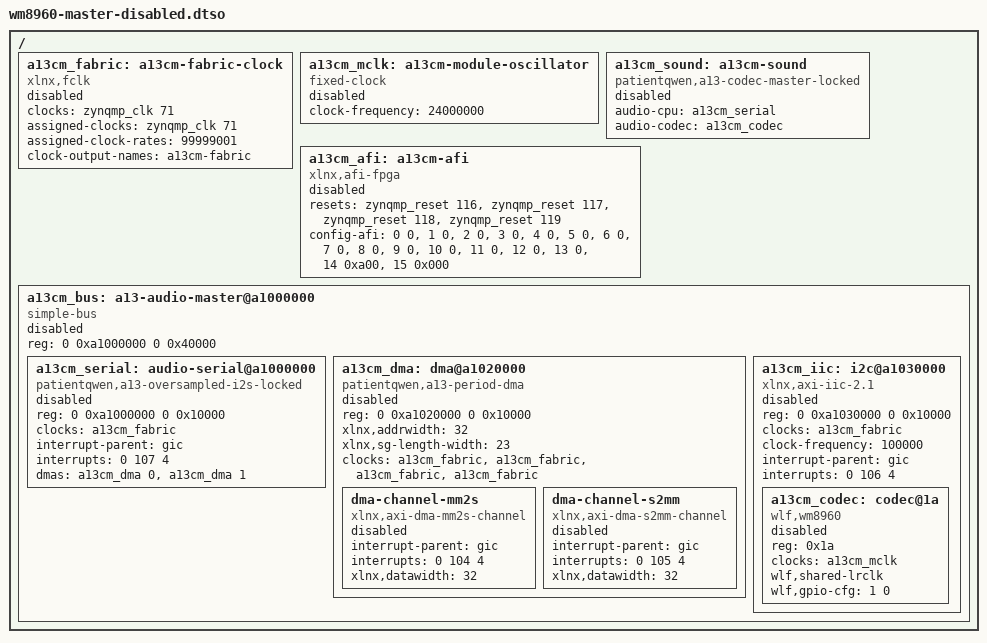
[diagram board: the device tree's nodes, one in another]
/dts-v1/;
/plugin/;

/* Offline candidate only: every new node remains disabled. No fpga-region. */
/ {
    fragment@0 {
        target-path = "/";
        __overlay__ {
            a13cm_fabric: a13cm-fabric-clock {
                compatible = "xlnx,fclk";
                #clock-cells = <0>;
                clocks = <&zynqmp_clk 71>;
                assigned-clocks = <&zynqmp_clk 71>;
                assigned-clock-rates = <99999001>;
                clock-output-names = "a13cm-fabric";
                status = "disabled";
            };
            a13cm_mclk: a13cm-module-oscillator {
                compatible = "fixed-clock";
                #clock-cells = <0>;
                clock-frequency = <24000000>;
                status = "disabled";
            };
            a13cm_sound: a13cm-sound {
                compatible = "patientqwen,a13-codec-master-locked";
                audio-cpu = <&a13cm_serial>;
                audio-codec = <&a13cm_codec>;
                status = "disabled";
            };
            a13cm_afi: a13cm-afi {
                compatible = "xlnx,afi-fpga";
                resets = <&zynqmp_reset 116>, <&zynqmp_reset 117>, <&zynqmp_reset 118>, <&zynqmp_reset 119>;
                config-afi = <0 0>, <1 0>, <2 0>, <3 0>, <4 0>, <5 0>, <6 0>, <7 0>, <8 0>, <9 0>, <10 0>, <11 0>, <12 0>, <13 0>, <14 0xa00>, <15 0x000>;
                status = "disabled";
            };
        };
    };
    fragment@1 {
        target-path = "/";
        __overlay__ {
            #address-cells = <2>;
            #size-cells = <2>;
            a13cm_bus: a13-audio-master@a1000000 {
                compatible = "simple-bus";
                reg = <0 0xa1000000 0 0x40000>;
                #address-cells = <2>;
                #size-cells = <2>;
                ranges = <0 0xa1000000 0 0xa1000000 0 0x40000>;
                status = "disabled";
            a13cm_serial: audio-serial@a1000000 {
                compatible = "patientqwen,a13-oversampled-i2s-locked";
                reg = <0 0xa1000000 0 0x10000>;
                #sound-dai-cells = <0>;
                clocks = <&a13cm_fabric>;
                clock-names = "s_axi_aclk";
                interrupt-parent = <&gic>;
                interrupts = <0 107 4>;
                dmas = <&a13cm_dma 0>, <&a13cm_dma 1>;
                dma-names = "tx", "rx";
                status = "disabled";
            };
            a13cm_dma: dma@a1020000 {
                compatible = "patientqwen,a13-period-dma";
                reg = <0 0xa1020000 0 0x10000>;
                #dma-cells = <1>;
                xlnx,addrwidth = <32>;
                xlnx,sg-length-width = <23>;
                clocks = <&a13cm_fabric>, <&a13cm_fabric>, <&a13cm_fabric>, <&a13cm_fabric>;
                clock-names = "s_axi_lite_aclk", "m_axi_mm2s_aclk", "m_axi_s2mm_aclk", "m_axi_sg_aclk";
                status = "disabled";
                dma-channel-mm2s {
                    compatible = "xlnx,axi-dma-mm2s-channel";
                    interrupt-parent = <&gic>;
                    interrupts = <0 104 4>;
                    xlnx,datawidth = <32>;
                    status = "disabled";
                };
                dma-channel-s2mm {
                    compatible = "xlnx,axi-dma-s2mm-channel";
                    interrupt-parent = <&gic>;
                    interrupts = <0 105 4>;
                    xlnx,datawidth = <32>;
                    status = "disabled";
                };
            };
            a13cm_iic: i2c@a1030000 {
                compatible = "xlnx,axi-iic-2.1", "xlnx,xps-iic-2.00.a";
                reg = <0 0xa1030000 0 0x10000>;
                #address-cells = <1>;
                #size-cells = <0>;
                clocks = <&a13cm_fabric>;
                clock-frequency = <100000>;
                interrupt-parent = <&gic>;
                interrupts = <0 106 4>;
                status = "disabled";
                a13cm_codec: codec@1a {
                    compatible = "wlf,wm8960";
                    reg = <0x1a>;
                    #sound-dai-cells = <0>;
                    clocks = <&a13cm_mclk>;
                    clock-names = "mclk";
                    wlf,shared-lrclk;
                    wlf,gpio-cfg = <1 0>;
                    status = "disabled";
                };
            };
            };
        };
    };
};
